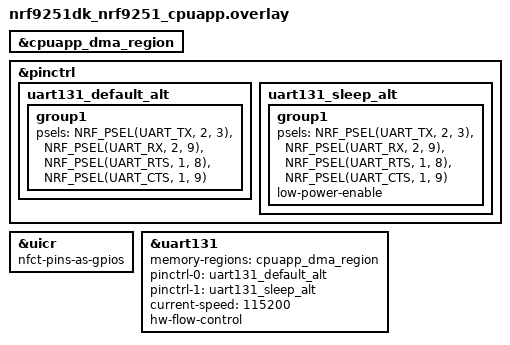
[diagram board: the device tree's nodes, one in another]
/*
 * Copyright (c) 2026 Nordic Semiconductor ASA
 *
 * SPDX-License-Identifier: LicenseRef-Nordic-5-Clause
 */

/* Test requires loopbacks:
 * TX-RX: P2.03 - P2.09
 * RTS-CTS: P1.08 - P1.09 (connected with NFCT antena)
 */

&cpuapp_dma_region {
	status = "okay";
};

&pinctrl {
	uart131_default_alt: uart131_default_alt {
		group1 {
			psels = <NRF_PSEL(UART_TX, 2, 3)>,
				<NRF_PSEL(UART_RX, 2, 9)>,
				<NRF_PSEL(UART_RTS, 1, 8)>,
				<NRF_PSEL(UART_CTS, 1, 9)>;
		};
	};

	uart131_sleep_alt: uart131_sleep_alt {
		group1 {
			psels = <NRF_PSEL(UART_TX, 2, 3)>,
				<NRF_PSEL(UART_RX, 2, 9)>,
				<NRF_PSEL(UART_RTS, 1, 8)>,
				<NRF_PSEL(UART_CTS, 1, 9)>;
			low-power-enable;
		};
	};
};

&uicr {
	nfct-pins-as-gpios;
};

dut: &uart131 {
	status = "okay";
	memory-regions = <&cpuapp_dma_region>;
	pinctrl-0 = <&uart131_default_alt>;
	pinctrl-1 = <&uart131_sleep_alt>;
	pinctrl-names = "default", "sleep";
	current-speed = <115200>;
	hw-flow-control;
};
